# S32K312_M7 register map
Vendor: NXP Semiconductors; File version: 1.3
CPU: CM7 r0p1, little endian, MPU, FPU, VTOR, 4 interrupt priority bits
Registers are 32-bit, read-write, reset 0x0 unless marked. A register's access mark holds for its fields unless they carry their own. Offsets are from the block's base; [hi:lo] are bit positions; {n}, {i} and the like mark numbered series; 'fields as' and 'values as' point back to an identical list.

## FLASH — c40asf flash memory
Base 0x402EC000
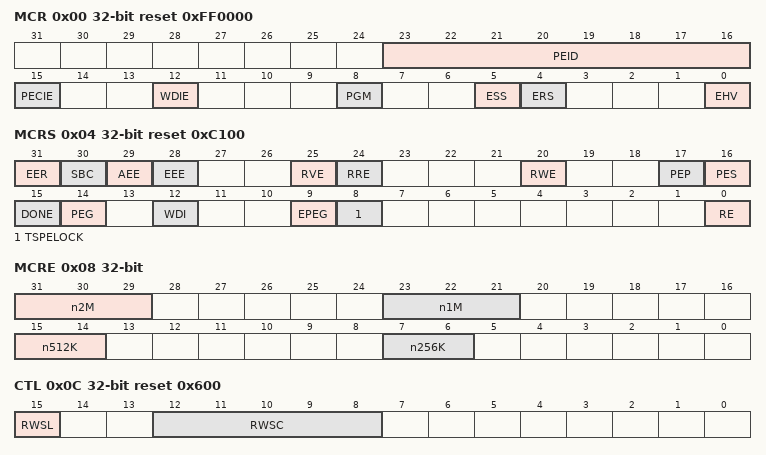
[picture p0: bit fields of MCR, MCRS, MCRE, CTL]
0x00 MCR reset 0xFF0000 — Module Configuration
  [23:16] PEID ro — Program and Erase Master/Domain ID
  [15] PECIE — Program/Erase Complete Interrupt Enable
    0=Interrupt request not generated when MCRS[DONE] is 1; 1=Interrupt request generated when MCRS[DONE] is 1
  [12] WDIE — Watch Dog Interrupt Enable
    0=Watchdog interrupt not enabled; 1=Watchdog interrupt enabled
  [8] PGM — Program
    0=Flash memory not executing a program sequence; 1=Flash memory executing a program sequence
  [5] ESS — Erase Size Select
    0=Flash memory erase is on a sector; 1=Flash memory erase is on a block
  [4] ERS — Erase
    0=Flash memory not executing an erase sequence; 1=Flash memory executing an erase sequence
  [0] EHV — Enable High Voltage
    0=Flash memory is not enabled to perform a high voltage operation; 1=Flash memory is enabled to perform a high voltage operation
0x04 MCRS reset 0xC100 — Module Configuration Status
  [31] EER write-1-clears — ECC Event Error
    0=Reads occurring normally; 1=ECC error occurred during a previous read
  [30] SBC write-1-clears — Single Bit Correction
    0=Reads occurring without corrections; 1=Single bit correction occurred during a previous read
  [29] AEE write-1-clears — Address Encode Error
    0=Reads are occurring without address encode mismatches; 1=Previous read may be corrupted based on address encode mismatch
  [28] EEE write-1-clears — EDC after ECC Error
    0=Reads are occurring without EDC after ECC mismatches; 1=Previous read may be corrupted based on ECC calculation errors
  [25] RVE write-1-clears — Read Voltage Error
    0=Reads are occurring without voltage issues; 1=A previous read may have been corrupted due to read voltage being out of range
  [24] RRE write-1-clears — Read Reference Error
    0=Reads occur without reference issues; 1=Previous read may be corrupted because of read reference being out of range
  [20] RWE write-1-clears — Read-While-Write Event Error
    0=Reads occur normally; 1=RWW error occurred during a previous read
  [17] PEP write-1-clears — Program and Erase Protection Error
    0=Program and erase protection errors do not exist; 1=Previous program or erase protection error encountered
  [16] PES write-1-clears — Program and Erase Sequence Error
    0=Program and erase sequence errors do not exist; 1=Previous program or erase sequence encountered an error
  [15] DONE ro — State Machine Status
    0=Performing a high voltage operation; 1=Not executing a high voltage operation
  [14] PEG ro — Program/Erase Good
    0=Program or erase operation failed; 1=Program or erase operation successful
  [12] WDI ro — Watch Dog Interrupt
    0=Normal Operation, Watchdog Timer has not expired; 1=Program Watchdog Timer has expired
  [9] EPEG ro — ECC Enabled Program/Erase Good
    0=Program or erase operation did not require ECC Enabled verifies; 1=Program or erase operation required ECC Enabled verifies to pass
  [8] TSPELOCK ro — UTest NVM Program and Erase Lock
    0=Corresponding sector not locked, and may be programmed or erased; 1=Corresponding sector protected from the program and erase sequences
  [0] RE ro — Reset Error
    0=Reset occurred without errors; 1=Reset error encountered
0x08 MCRE ro — Extended Module Configuration
  [31:29] n2M — Number of 2 MB Blocks
    0=Zero 2 MB blocks; 1=One 2 MB block; 2=Two 2 MB blocks; 3=Three 2 MB blocks; 4=Four 2 MB blocks
  [23:21] n1M — Number of 1 MB Blocks
    0=Zero 1 MB blocks; 1=One 1 MB block; 2=Two 1 MB blocks; 3=Three 1 MB blocks; 4=Four 1 MB blocks
  [15:14] n512K — Number of 512 KB Blocks
    0=Zero 512 KB blocks; 1=One 512 KB block; 2=Two 512 KB blocks; 3=Four 512 KB blocks
  [7:6] n256K — Number of 256 KB Blocks
    0=Zero 256 KB blocks; 1=One 256 KB block; 2=Two 256 KB blocks; 3=Four 256 KB blocks
0x0C CTL reset 0x600 — Module Control
  [15] RWSL — Read Wait State Lock
    0=RWSC not locked and available for writing; 1=RWSC locked and unavailable for writing
  [12:8] RWSC — Wait State Control
    1=One additional wait state is added; 2=Two additional wait states are added; 3=Three additional wait states are added; 4=Four additional wait states are added; 5=Five additional wait states are added; 6=Six additional wait states are added; 7=Seven additional wait states are added; 8=Eight additional wait states are added
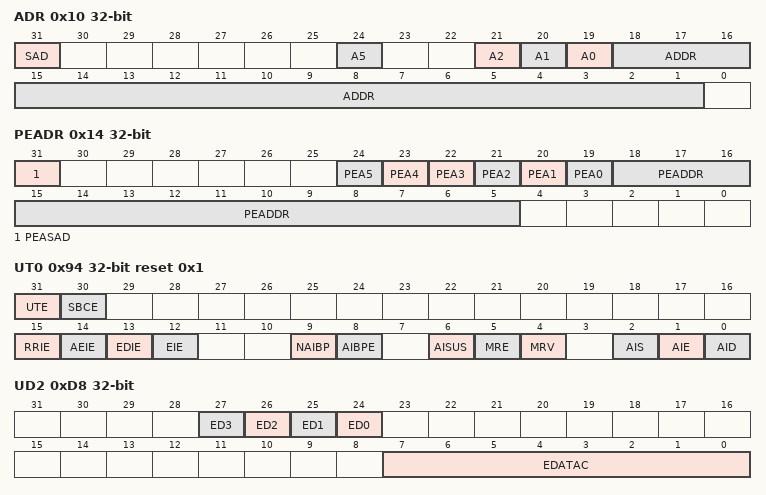
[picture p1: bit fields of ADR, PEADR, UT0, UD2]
0x10 ADR — Address
  [31] SAD — UTest NVM Address
    0=Address captured or to be accessed is from the main array space; 1=Address captured or to be accessed is from the UTest NVM array space
  [24] A5 — Address Region 5
    0=Address captured or to be accessed is not from region 5; 1=Address captured or to be accessed is from region 5
  [21] A2 — Address Region 2
    0=Address captured or to be accessed is not from region 2; 1=Address captured or to be accessed is from region 2
  [20] A1 — Address Region 1
    0=Address captured or to be accessed is not from region 1; 1=Address captured or to be accessed is from region 1
  [19] A0 — Address Region 0
    0=Address captured or to be accessed is not from region 0; 1=Address captured or to be accessed is from region 0
  [18:1] ADDR — Address
0x14 PEADR ro — Program and Erase Address
  [31] PEASAD — UTest NVM Program and Erase Address
    0=Address accessed is from the main array space; 1=Address accessed is from the UTest NVM array space
  [24] PEA5 — Program and Erase Address Region 5
    0=Address accessed is not from region 5; 1=Address accessed is from region 5
  [23] PEA4 — Program and Erase Address Region 4
    0=Address accessed is not from region 4; 1=Adrress accessed is from region 4
  [n+19] PEA{n} (n=0..3) — Program and Erase Address Region {n}
    0=Address accessed is not from region {n}; 1=Address accessed is from region {n}
  [18:5] PEADDR — Program and Erase Address
0x50 SPELOCK ro reset 0xFFFFFFFF — Sector Program and Erase Hardware Lock
  [31:0] SPELOCK — Sector Program and Erase Lock [31:0]
0x54 SSPELOCK ro reset 0xFFFFFFF — Super Sector Program and Erase Hardware Lock
  [27:0] SSPELOCK — Super Sector Program and Erase Lock [27:0]
0x70 XSPELOCK ro reset 0xFFFFFFFF — Express Sector Program and Erase Hardware Lock
  [31:0] XSPELOCK — Express Sector Program and Erase Lock [31:0]
0x74 XSSPELOCK ro reset 0xFFFFFFF — Express Super Sector Program and Erase Hardware Lock
  [27:0] XSSPELOCK — Express Super Sector Program and Erase Lock [27:0]
0x90 TMD — Test Mode Disable Password Check
  [31:0] PWD — Password Challenge
0x94 UT0 reset 0x1 — UTest 0
  [31] UTE — UTest Enable
    0=U-Test mode is not enabled; 1=U-Test mode is enabled
  [30] SBCE — Single Bit Correction Enable
    0=Disabled; 1=Enabled
  [15] RRIE — Read Reference Input Enable
    0=Read reference input disabled; 1=Read reference input enabled
  [14] AEIE — Address Encode Invert Enable
    0=Address encode invert is disabled; 1=Address encode values are inverted based on UA0[AEI]
  [13] EDIE — EDC after ECC Data Input Enable
    0=EDC after ECC data input is disabled; 1=Data read is from UD3[EDDATA] and UD5[EDDATAC]
  [12] EIE — ECC Data Input Enable
    0=ECC data input is disabled; 1=Data read is from UD0[EDATA] and UD2[EDATAC]
  [9] NAIBP — Next Array Integrity Break Point
    0=Array integrity state machine is not currently at a breakpoint; 1=Array integrity state machine is at a breakpoint
  [8] AIBPE — Array Integrity Break Point Enable
    0=Array integrity breakpoints disabled; 1=Array integrity breakpoints enabled during array integrity checks
  [6] AISUS — Array Integrity Suspend
    0=Array integrity sequence not suspended; 1=Array integrity sequence is suspended
  [5] MRE — Margin Read Enable
    0=Margin reads are not enabled; 1=Margin reads are enabled
  [4] MRV — Margin Read Value
    0=Zero's margin reads are requested; 1=One's margin reads are requested
  [2] AIS — Array Integrity Sequence
    0=Array integrity sequence is proprietary sequence; 1=Array integrity sequence is sequential
  [1] AIE — Array Integrity Enable
    0=Array integrity checks not enabled; 1=Array integrity checks enabled
  [0] AID ro — Array Integrity Done
    0=Array integrity check ongoing; 1=Array integrity check complete
{0x98+4i} UM[{i}] (i=0..8) — UMISRn
  [31:0] MISR — MISR[31:0]
0xBC UM9 — UMISR9
  [0] MISR — MISR[288]
0xD0 UD0 — UTest Data 0
  [31:0] EDATA — ECC Data [31:0]
0xD4 UD1 — UTest Data 1
  [31:0] EDATA — ECC Data [63:32]
0xD8 UD2 — UTest Data 2
  [n+24] ED{n} (n=0..3) — ECC Logic Check Double Word {n}
  [7:0] EDATAC — ECC Data Check Bits [7:0]
0xDC UD3 — UTest Data 3
  [31:0] EDDATA — EDC After ECC Data [31:0]
0xE0 UD4 — UTest Data 4
  [31:0] EDDATA — EDC After ECC Data [63:31]
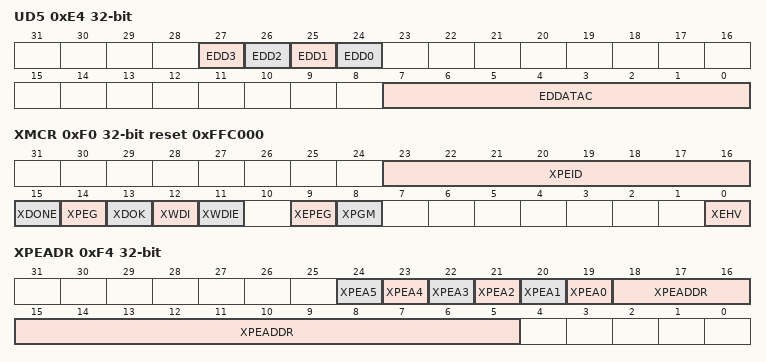
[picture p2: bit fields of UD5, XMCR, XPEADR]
0xE4 UD5 — UTest Data 5
  [27] EDD3 — EDC After ECC Logic Check Double Word 3
  [26] EDD2 — EDC after ECC Logic Check Double Word 2
  [25] EDD1 — EDC After ECC Logic Check Double Word 1
  [24] EDD0 — EDC After ECC Logic Check Double Word 0
  [7:0] EDDATAC — EDC After ECC Data Check Bits [7:0]
0xE8 UA0 — UTest Address 0
  [31:0] AEI — Address Encode Invert [31:0]
0xEC UA1 — UTest Address 1
  [19:0] AEI — Address Encode Invert [51:32]
0xF0 XMCR reset 0xFFC000 — Express Module Configuration
  [23:16] XPEID ro — Express Program Master/Domain ID
  [15] XDONE ro — Express State Machine Status
    0=Executing an express program operation; 1=Not executing an express program operation
  [14] XPEG ro — Express Program Good
    0=Program operation failed; 1=Program operation successful
  [13] XDOK ro — Express Data OK
    0=Flash memory not ready to accept writes to the DATA registers; 1=Writes to DATA registers allowed
  [12] XWDI ro — Express Watch Dog Interrupt
    0=Normal Operation, Watchdog Timer has not expired; 1=Express Program Watchdog Timer has expired
  [11] XWDIE — Express Watch Dog Interrupt Enable
    0=Express watchdog interrupt disabled; 1=Express watchdog interrupt enabled
  [9] XEPEG ro — Express ECC Enabled Program Good
    0=Program operation did not require ECC-enabled verifies; 1=Program operation required ECC-enabled verifies to pass
  [8] XPGM — Express Program
    0=Flash memory not executing an express program sequence; 1=Flash memory executing an express program sequence
  [0] XEHV — Express Enable High Voltage
    0=Flash memory is not enabled to perform an express high voltage operation; 1=Flash memory is enabled to perform an express high voltage operation
0xF4 XPEADR ro — Express Program Address
  [n+19] XPEA{n} (n=0..5) — Express Program Address Region {n}
    values as PEADR.PEA0
  [18:5] XPEADDR — Express Program Address
{0x100+4i} DATA[{i}] (i=0..31) reset 0xFFFFFFFF — Program Data
  [31:0] PDATA
